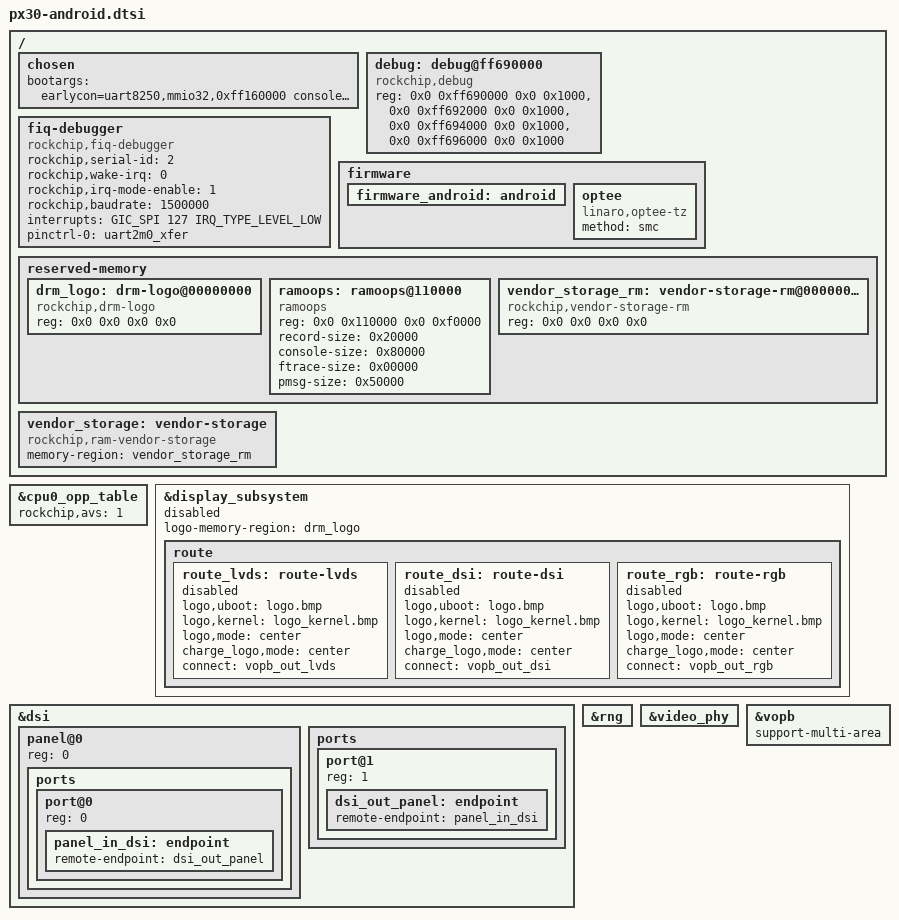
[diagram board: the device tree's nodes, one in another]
/*
 * Copyright (c) 2017 Fuzhou Rockchip Electronics Co., Ltd
 *
 * SPDX-License-Identifier: (GPL-2.0+ OR MIT)
 */

/ {
	chosen: chosen {
		bootargs = "earlycon=uart8250,mmio32,0xff160000 console=ttyFIQ0 init=/init kpti=0";
	};

	debug: debug@ff690000 {
		compatible = "rockchip,debug";
		reg = <0x0 0xff690000 0x0 0x1000>,
		      <0x0 0xff692000 0x0 0x1000>,
		      <0x0 0xff694000 0x0 0x1000>,
		      <0x0 0xff696000 0x0 0x1000>;
	};

	fiq-debugger {
		compatible = "rockchip,fiq-debugger";
		rockchip,serial-id = <2>;
		rockchip,wake-irq = <0>;
		/* If enable uart uses irq instead of fiq */
		rockchip,irq-mode-enable = <1>;
		rockchip,baudrate = <1500000>;  /* Only 115200 and 1500000 */
		interrupts = <GIC_SPI 127 IRQ_TYPE_LEVEL_LOW>;
		pinctrl-names = "default";
		pinctrl-0 = <&uart2m0_xfer>;
		status = "okay";
	};

	firmware {
		firmware_android: android {};

		optee: optee {
			compatible = "linaro,optee-tz";
			method = "smc";
		};
	};

	reserved-memory {
		#address-cells = <2>;
		#size-cells = <2>;
		ranges;

		drm_logo: drm-logo@00000000 {
			compatible = "rockchip,drm-logo";
			reg = <0x0 0x0 0x0 0x0>;
		};

		ramoops: ramoops@110000 {
			compatible = "ramoops";
			reg = <0x0 0x110000 0x0 0xf0000>;
			record-size = <0x20000>;
			console-size = <0x80000>;
			ftrace-size = <0x00000>;
			pmsg-size = <0x50000>;
		};

		vendor_storage_rm: vendor-storage-rm@00000000 {
			compatible = "rockchip,vendor-storage-rm";
			reg = <0x0 0x0 0x0 0x0>;
		};
	};

	vendor_storage: vendor-storage {
		compatible = "rockchip,ram-vendor-storage";
		memory-region = <&vendor_storage_rm>;
		status = "okay";
	};
};

&cpu0_opp_table {
	rockchip,avs = <1>;
};

&display_subsystem {
	status = "disabled";
	logo-memory-region = <&drm_logo>;

	route {
		route_lvds: route-lvds {
			status = "disabled";
			logo,uboot = "logo.bmp";
			logo,kernel = "logo_kernel.bmp";
			logo,mode = "center";
			charge_logo,mode = "center";
			connect = <&vopb_out_lvds>;
		};

		route_dsi: route-dsi {
			status = "disabled";
			logo,uboot = "logo.bmp";
			logo,kernel = "logo_kernel.bmp";
			logo,mode = "center";
			charge_logo,mode = "center";
			connect = <&vopb_out_dsi>;
		};

		route_rgb: route-rgb {
			status = "disabled";
			logo,uboot = "logo.bmp";
			logo,kernel = "logo_kernel.bmp";
			logo,mode = "center";
			charge_logo,mode = "center";
			connect = <&vopb_out_rgb>;
		};
	};
};

&dsi {
	panel@0 {
		reg = <0>;

		ports {
			#address-cells = <1>;
			#size-cells = <0>;

			port@0 {
				reg = <0>;

				panel_in_dsi: endpoint {
					remote-endpoint = <&dsi_out_panel>;
				};
			};
		};
	};

	ports {
		#address-cells = <1>;
		#size-cells = <0>;

		port@1 {
			reg = <1>;

			dsi_out_panel: endpoint {
				remote-endpoint = <&panel_in_dsi>;
			};
		};
	};
};

&rng {
	status = "okay";
};

&video_phy {
	status = "okay";
};

&vopb {
	support-multi-area;
};
